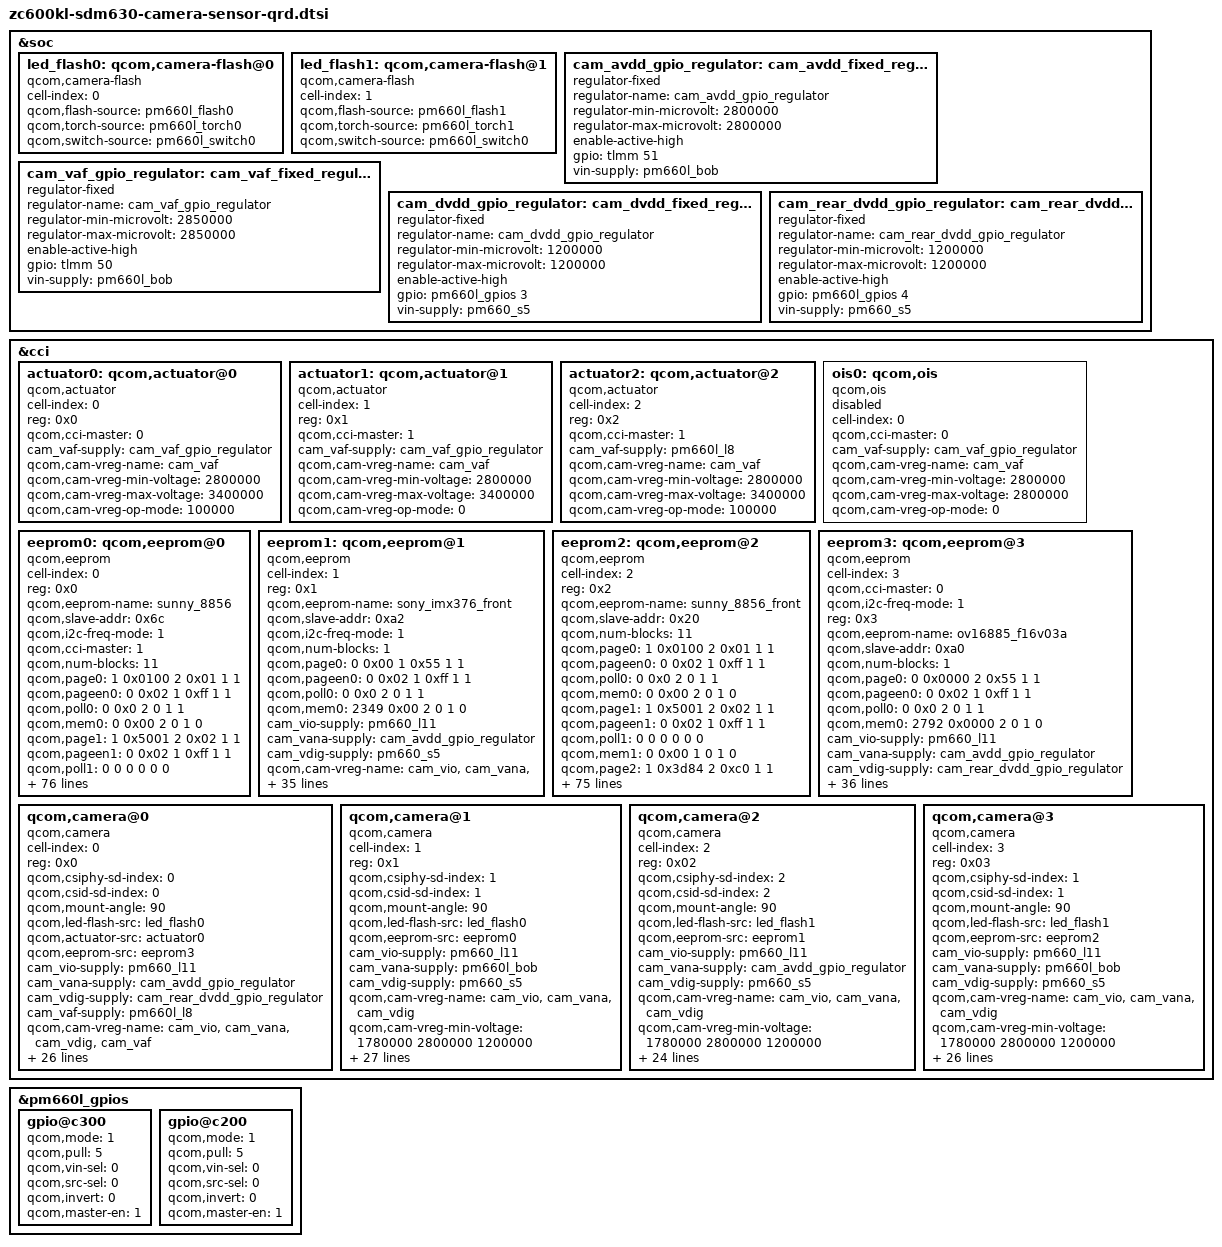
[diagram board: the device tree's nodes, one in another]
/*
 * Copyright (c) 2017, The Linux Foundation. All rights reserved.
 *
 * This program is free software; you can redistribute it and/or modify
 * it under the terms of the GNU General Public License version 2 and
 * only version 2 as published by the Free Software Foundation.
 *
 * This program is distributed in the hope that it will be useful,
 * but WITHOUT ANY WARRANTY; without even the implied warranty of
 * MERCHANTABILITY or FITNESS FOR A PARTICULAR PURPOSE.  See the
 * GNU General Public License for more details.
 */

&soc {
	led_flash0: qcom,camera-flash@0 {
		cell-index = <0>;
		compatible = "qcom,camera-flash";
		qcom,flash-source = <&pm660l_flash0>;
		qcom,torch-source = <&pm660l_torch0>;
		qcom,switch-source = <&pm660l_switch0>;
		status = "ok";
	};

	led_flash1: qcom,camera-flash@1 {
		cell-index = <1>;
		compatible = "qcom,camera-flash";
		qcom,flash-source = <&pm660l_flash1>;
		qcom,torch-source = <&pm660l_torch1>;
		qcom,switch-source = <&pm660l_switch0>;
		status = "ok";
	};
	cam_avdd_gpio_regulator: cam_avdd_fixed_regulator {
		compatible = "regulator-fixed";
		regulator-name = "cam_avdd_gpio_regulator";
		regulator-min-microvolt = <2800000>;
		regulator-max-microvolt = <2800000>;
		enable-active-high;
		gpio = <&tlmm 51 0>;
		vin-supply = <&pm660l_bob>;
	};

	cam_vaf_gpio_regulator: cam_vaf_fixed_regulator {
		compatible = "regulator-fixed";
		regulator-name = "cam_vaf_gpio_regulator";
		regulator-min-microvolt = <2850000>;
		regulator-max-microvolt = <2850000>;
		enable-active-high;
		gpio = <&tlmm 50 0>;
		vin-supply = <&pm660l_bob>;
	};
	cam_dvdd_gpio_regulator: cam_dvdd_fixed_regulator {
		compatible = "regulator-fixed";
		regulator-name = "cam_dvdd_gpio_regulator";
		regulator-min-microvolt = <1200000>;
		regulator-max-microvolt = <1200000>;
		enable-active-high;
		gpio = <&pm660l_gpios 3 0>;
		vin-supply = <&pm660_s5>;
	};
	cam_rear_dvdd_gpio_regulator: cam_rear_dvdd_fixed_regulator {
		compatible = "regulator-fixed";
		regulator-name = "cam_rear_dvdd_gpio_regulator";
		regulator-min-microvolt = <1200000>;
		regulator-max-microvolt = <1200000>;
		enable-active-high;
		gpio = <&pm660l_gpios 4 0>;
		vin-supply = <&pm660_s5>;
	};
};

&cci {
	actuator0: qcom,actuator@0 {
		cell-index = <0>;
		reg = <0x0>;
		compatible = "qcom,actuator";
		qcom,cci-master = <0>;
		cam_vaf-supply = <&cam_vaf_gpio_regulator>;
		qcom,cam-vreg-name = "cam_vaf";
		qcom,cam-vreg-min-voltage = <2800000>;
		qcom,cam-vreg-max-voltage = <3400000>;
		qcom,cam-vreg-op-mode = <100000>;
	};

	actuator1: qcom,actuator@1 {
		cell-index = <1>;
		reg = <0x1>;
		compatible = "qcom,actuator";
		qcom,cci-master = <1>;
		cam_vaf-supply = <&cam_vaf_gpio_regulator>;
		qcom,cam-vreg-name = "cam_vaf";
		qcom,cam-vreg-min-voltage = <2800000>;
		qcom,cam-vreg-max-voltage = <3400000>;
		qcom,cam-vreg-op-mode = <0>;
	};

	actuator2: qcom,actuator@2 {
		cell-index = <2>;
		reg = <0x2>;
		compatible = "qcom,actuator";
		qcom,cci-master = <1>;
		cam_vaf-supply = <&pm660l_l8>;
		qcom,cam-vreg-name = "cam_vaf";
		qcom,cam-vreg-min-voltage = <2800000>;
		qcom,cam-vreg-max-voltage = <3400000>;
		qcom,cam-vreg-op-mode = <100000>;
	};
	ois0: qcom,ois {
		cell-index = <0>;
		compatible = "qcom,ois";
		qcom,cci-master = <0>;
		cam_vaf-supply = <&cam_vaf_gpio_regulator>;
		qcom,cam-vreg-name = "cam_vaf";
		qcom,cam-vreg-min-voltage = <2800000>;
		qcom,cam-vreg-max-voltage = <2800000>;
		qcom,cam-vreg-op-mode = <0>;
		status = "disabled";
	};

	eeprom0: qcom,eeprom@0 {
		cell-index = <0>;
		reg = <0x0>;
		compatible = "qcom,eeprom";
		
        //add by allenyao
		qcom,eeprom-name = "sunny_8856";
		qcom,slave-addr = <0x6c>;
		qcom,i2c-freq-mode=<1>;
		qcom,cci-master = <1>;
		qcom,num-blocks = <11>;
		
		qcom,page0 = <1 0x0100 2 0x01 1 1>;
		qcom,pageen0 = <0 0x02 1 0xff 1 1>;
		qcom,poll0 = <0 0x0 2 0 1 1>;
		qcom,mem0 = <0 0x00 2 0 1 0>;

		qcom,page1 = <1 0x5001 2 0x02 1 1>;
		qcom,pageen1 = <0 0x02 1 0xff 1 1>;
		qcom,poll1 = <0 0 0 0 0 0>;
		qcom,mem1 = <0 0x00 1 0 1 0>;
		
		qcom,page2 = <1 0x3d84 2 0xc0 1 1>;
		qcom,pageen2 = <0 0x02 1 0xff 1 1>;
		qcom,poll2 = <0 0 0 0 0 0>;
		qcom,mem2 = <0 0x00 1 0 1 0>;

		qcom,page3 = <1 0x3d88 2 0x70 1 1>;//start high add
		qcom,pageen3 = <0 0x02 1 0xff 1 1>;
		qcom,poll3 = <0 0 0 0 0 0>;
		qcom,mem3 = <0 0x00 1 0 1 0>;
		
		qcom,page4 = <1 0x3d89 2 0x10 1 1>;//start low add
		qcom,pageen4 = <0 0x02 1 0xff 1 1>;
		qcom,poll4 = <0 0 0 0 0 0>;
		qcom,mem4 = <0 0x00 1 0 1 0>;
		
		qcom,page5 = <1 0x3d8a 2 0x72 1 1>;//end high add
		qcom,pageen5 = <0 0x02 1 0xff 1 1>;
		qcom,poll5 = <0 0 0 0 0 0>;
		qcom,mem5 = <0 0x00 1 0 1 0>;

		qcom,page6 = <1 0x3d8b 2 0x03 1 1>;//end low add
		qcom,pageen6 = <0 0x02 1 0xff 1 1>;
		qcom,poll6 = <0 0 0 0 0 0>;
		qcom,mem6 = <0 0x00 1 0 1 0>;

		qcom,page7 = <1 0x3d81 2 0x01 1 10>;//load otp data into buffer
		qcom,pageen7 = <0 0x02 1 0xff 1 1>;
		qcom,poll7 = <0 0 0 0 0 0>;
		qcom,mem7 = <0 0x7203 2 0 1 0>;

		qcom,page8 = <0 0x00 1 0x11 1 1>;
		qcom,pageen8 = <0 0x02 1 0xff 1 1>;
		qcom,poll8 = <0 0 0 0 0 0>;
		qcom,mem8 = <500 0x7010 2 0 1 0>; //read data
		
		qcom,page9 = <0 0x00 1 0x11 1 1>;
		qcom,pageen9 = <0 0x02 1 0xff 1 1>;
		qcom,poll9 = <0 0 0 0 0 0>;
		qcom,mem9 = <0 0x00 1 0 1 0>;
		qcom,clear9 = <500 0x7010 2 0 1 0>; //clear buff

		qcom,page10 = <1 0x5001 2 0x0a 1 1>;
		qcom,pageen10 = <0 0x02 1 0xff 1 1>;
		qcom,poll10 = <0 0 0 0 0 0>;
		qcom,mem10 = <0 0x7203 2 0 1 0>;
		//end 

		cam_vio-supply = <&pm660_l11>;
		cam_vana-supply = <&pm660l_bob>;
		cam_vdig-supply = <&pm660_s5>;
		qcom,cam-vreg-name = "cam_vio", "cam_vana", "cam_vdig";
		qcom,cam-vreg-min-voltage = <1780000 2800000 1200000>;
		qcom,cam-vreg-max-voltage = <1950000 2800000 1200000>;
		qcom,cam-vreg-op-mode = <105000 80000 100000>;
		qcom,gpio-no-mux = <0>;
		pinctrl-names = "cam_default", "cam_suspend";
		pinctrl-0 = <&cam_sensor_mclk2_active
				 &cam_sensor_rear2_active>;
		pinctrl-1 = <&cam_sensor_mclk2_suspend
				 &cam_sensor_rear2_suspend>;
		gpios = <&tlmm 34 0>,
			<&tlmm 64 0>,
		    <&tlmm 40 0>,
		    <&pm660l_gpios 4 0>,
		    <&tlmm 51 0>;
		qcom,gpio-reset = <1>;
		qcom,gpio-standby = <2>;
		qcom,gpio-vdig = <3>;
		qcom,gpio-vana = <4>;
		qcom,gpio-req-tbl-num = <0 1 2 3 4>;
		qcom,gpio-req-tbl-flags = <1 0 0 0 0>;
		qcom,gpio-req-tbl-label = "CAMIF_MCLK2",
					  "CAM_RESET",
					  "CAM_STANDBY",
					  "CAM_VDIG",
					  "CAM_VANA";
		qcom,sensor-position = <0>;
		qcom,sensor-mode = <0>;

		qcom,cam-power-seq-type = "sensor_gpio",
			"sensor_gpio", "sensor_vreg",
			"sensor_vreg", "sensor_clk",
			"sensor_gpio";
		qcom,cam-power-seq-val = "sensor_gpio_reset",
			"sensor_gpio_vana", "cam_vdig",
			"cam_vio",
			"sensor_cam_mclk",
			"sensor_gpio_reset";
		qcom,cam-power-seq-cfg-val = <0  1 1 1 24000000 1>;
		qcom,cam-power-seq-delay = <10 10 10 10 10 5>;

		status = "ok";

		clocks = <&clock_mmss MCLK2_CLK_SRC>,
			<&clock_mmss MMSS_CAMSS_MCLK2_CLK>;
		clock-names = "cam_src_clk", "cam_clk";
		qcom,clock-rates = <24000000 0>;
	};

	eeprom1: qcom,eeprom@1 {
		cell-index = <1>;
		reg = <0x1>;
		compatible = "qcom,eeprom";

		qcom,eeprom-name = "sony_imx376_front";
		qcom,slave-addr = <0xa2>;
		qcom,i2c-freq-mode=<1>;
		qcom,num-blocks = <1>;	
		qcom,page0 = <0 0x00 1 0x55 1 1>;
		qcom,pageen0 = <0 0x02 1 0xff 1 1>;
		qcom,poll0 = <0 0x0 2 0 1 1>;
		qcom,mem0 = <2349 0x00 2 0 1 0>;
		
		cam_vio-supply = <&pm660_l11>;
		cam_vana-supply = <&cam_avdd_gpio_regulator>;
		cam_vdig-supply = <&pm660_s5>;
		qcom,cam-vreg-name = "cam_vio", "cam_vana", "cam_vdig";
		qcom,cam-vreg-min-voltage = <1780000 2800000 1200000>;
		qcom,cam-vreg-max-voltage = <1950000 2800000 1200000>;
		qcom,cam-vreg-op-mode = <105000 80000 100000>;
		qcom,gpio-no-mux = <0>;
		pinctrl-names = "cam_default", "cam_suspend";
		pinctrl-0 = <&cam_sensor_mclk0_active
				 &cam_sensor_front_active>;
		pinctrl-1 = <&cam_sensor_mclk0_suspend
				 &cam_sensor_front_suspend>;
		gpios = <&tlmm 32 0>,
			    <&tlmm 48 0>,
			    <&tlmm 52 0>,
			    <&pm660l_gpios 3 0>,
			    <&tlmm 51 0>;
		qcom,gpio-reset = <1>;
		qcom,gpio-standby = <2>;
		qcom,gpio-vdig = <3>;
		qcom,gpio-vana = <4>;
		qcom,gpio-req-tbl-num = <0 1 2 3 4>;
		qcom,gpio-req-tbl-flags = <1 0 0 0 0>;
		qcom,gpio-req-tbl-label = "CAMIF_MCLK0",
					"CAM_RESET2",
					"CAM_STANDBY2",
					"CAM_VDIG",
					"CAM_VANA";
		qcom,sensor-position = <1>;
		qcom,sensor-mode = <0>;
		qcom,cci-master = <0>;
		status = "ok";
		qcom,cam-power-seq-type = "sensor_gpio",
			"sensor_gpio", "sensor_gpio",
			"sensor_vreg", "sensor_clk",
			"sensor_gpio";
		qcom,cam-power-seq-val = "sensor_gpio_reset",
			"sensor_gpio_vana", "sensor_gpio_vdig",
			"cam_vio",
			"sensor_cam_mclk",
			"sensor_gpio_reset";
		qcom,cam-power-seq-cfg-val = <0  1 1 1 24000000 1>;
		qcom,cam-power-seq-delay = <10 10 10 10 10 5>;

		clocks = <&clock_mmss MCLK0_CLK_SRC>,
			<&clock_mmss MMSS_CAMSS_MCLK0_CLK>;
		clock-names = "cam_src_clk", "cam_clk";
		qcom,clock-rates = <24000000 0>;
	};

	eeprom2: qcom,eeprom@2 {
		cell-index = <2>;
		reg = <0x2>;
		compatible = "qcom,eeprom";
        //add by allenyao
		qcom,eeprom-name = "sunny_8856_front"; //Bug316366, sunhushan.wt, MODIFY, 2017.11.03, modify for 8856's OTP
		//compatible = "qcom,eeprom";
		qcom,slave-addr = <0x20>;
		qcom,num-blocks = <11>;
		
		qcom,page0 = <1 0x0100 2 0x01 1 1>;
		qcom,pageen0 = <0 0x02 1 0xff 1 1>;
		qcom,poll0 = <0 0x0 2 0 1 1>;
		qcom,mem0 = <0 0x00 2 0 1 0>;

		qcom,page1 = <1 0x5001 2 0x02 1 1>;
		qcom,pageen1 = <0 0x02 1 0xff 1 1>;
		qcom,poll1 = <0 0 0 0 0 0>;
		qcom,mem1 = <0 0x00 1 0 1 0>;
		
		qcom,page2 = <1 0x3d84 2 0xc0 1 1>;
		qcom,pageen2 = <0 0x02 1 0xff 1 1>;
		qcom,poll2 = <0 0 0 0 0 0>;
		qcom,mem2 = <0 0x00 1 0 1 0>;

		qcom,page3 = <1 0x3d88 2 0x70 1 1>;//start high add
		qcom,pageen3 = <0 0x02 1 0xff 1 1>;
		qcom,poll3 = <0 0 0 0 0 0>;
		qcom,mem3 = <0 0x00 1 0 1 0>;
		
		qcom,page4 = <1 0x3d89 2 0x10 1 1>;//start low add
		qcom,pageen4 = <0 0x02 1 0xff 1 1>;
		qcom,poll4 = <0 0 0 0 0 0>;
		qcom,mem4 = <0 0x00 1 0 1 0>;
		
		qcom,page5 = <1 0x3d8a 2 0x72 1 1>;//end high add
		qcom,pageen5 = <0 0x02 1 0xff 1 1>;
		qcom,poll5 = <0 0 0 0 0 0>;
		qcom,mem5 = <0 0x00 1 0 1 0>;

		qcom,page6 = <1 0x3d8b 2 0x03 1 1>;//end low add
		qcom,pageen6 = <0 0x02 1 0xff 1 1>;
		qcom,poll6 = <0 0 0 0 0 0>;
		qcom,mem6 = <0 0x00 1 0 1 0>;

		qcom,page7 = <1 0x3d81 2 0x01 1 10>;//load otp data into buffer
		qcom,pageen7 = <0 0x02 1 0xff 1 1>;
		qcom,poll7 = <0 0 0 0 0 0>;
		qcom,mem7 = <0 0x7203 2 0 1 0>;

		qcom,page8 = <0 0x00 1 0x11 1 1>;
		qcom,pageen8 = <0 0x02 1 0xff 1 1>;
		qcom,poll8 = <0 0 0 0 0 0>;
		qcom,mem8 = <500 0x7010 2 0 1 0>; //read data
		
		qcom,page9 = <0 0x00 1 0x11 1 1>;
		qcom,pageen9 = <0 0x02 1 0xff 1 1>;
		qcom,poll9 = <0 0 0 0 0 0>;
		qcom,mem9 = <0 0x00 1 0 1 0>;
		qcom,clear9 = <500 0x7010 2 0 1 0>; //clear buff

		qcom,page10 = <1 0x5001 2 0x0a 1 1>;
		qcom,pageen10 = <0 0x02 1 0xff 1 1>;
		qcom,poll10 = <0 0 0 0 0 0>;
		qcom,mem10 = <0 0x7203 2 0 1 0>;
		//end 
		cam_vio-supply = <&pm660_l11>;
		cam_vana-supply = <&pm660l_bob>;
		cam_vdig-supply = <&pm660_s5>;
		qcom,cam-vreg-name = "cam_vio", "cam_vana", "cam_vdig";
		qcom,cam-vreg-min-voltage = <1780000 2800000 1200000>;
		qcom,cam-vreg-max-voltage = <1950000 2800000 1200000>;
		qcom,cam-vreg-op-mode = <105000 80000 100000>;
		qcom,gpio-no-mux = <0>;
		pinctrl-names = "cam_default", "cam_suspend";
		pinctrl-0 = <&cam_sensor_mclk1_active
				 &cam_sensor_front_iris_active>;
		pinctrl-1 = <&cam_sensor_mclk1_suspend
				 &cam_sensor_front_iris_suspend>;
		gpios = <&tlmm 33 0>,
			<&tlmm 47 0>,
            <&tlmm 49 0>,
            <&pm660l_gpios 4 0>;
		qcom,gpio-reset = <1>;
		qcom,gpio-standby = <2>;
		qcom,gpio-vdig = <3>;
		qcom,gpio-req-tbl-num = <0 1 2 3>;
		qcom,gpio-req-tbl-flags = <1 0 0 0>;
		qcom,gpio-req-tbl-label = "CAMIF_MCLK",
					"CAM_RESET3",
		            "CAM_STANDBY3",
				    "CAM_VDIG";

		qcom,sensor-position = <1>;
		qcom,sensor-mode = <0>;
		qcom,cci-master = <1>;
		qcom,i2c-freq-mode=<1>;

		qcom,cam-power-seq-type = "sensor_gpio",
			"sensor_gpio", "sensor_vreg",
			"sensor_vreg", "sensor_clk",
			"sensor_gpio";
		qcom,cam-power-seq-val = "sensor_gpio_reset",
			"sensor_gpio_vana", "cam_vdig",
			"cam_vio",
			"sensor_cam_mclk",
			"sensor_gpio_reset";
		qcom,cam-power-seq-cfg-val = <0  1 1 1 24000000 1>;
		qcom,cam-power-seq-delay = <10 10 10 10 10 5>;	

		status = "ok";
		clocks = <&clock_mmss MCLK1_CLK_SRC>,
			<&clock_mmss MMSS_CAMSS_MCLK1_CLK>;
		clock-names = "cam_src_clk", "cam_clk";
		qcom,clock-rates = <24000000 0>;
 	};

    eeprom3: qcom,eeprom@3{
		cell-index = <3>;
		compatible = "qcom,eeprom";
		qcom,cci-master = <0>;
		qcom,i2c-freq-mode=<1>;
		reg = <0x3>;
		qcom,eeprom-name = "ov16885_f16v03a";
		qcom,slave-addr = <0xa0>;
		qcom,num-blocks = <1>;

        qcom,page0 = <0 0x0000 2 0x55 1 1>;
		qcom,pageen0 = <0 0x02 1 0xff 1 1>;
		qcom,poll0 = <0 0x0 2 0 1 1>;
		qcom,mem0 = <2792 0x0000 2 0 1 0>;

		cam_vio-supply = <&pm660_l11>;
		cam_vana-supply = <&cam_avdd_gpio_regulator>;
		cam_vdig-supply = <&cam_rear_dvdd_gpio_regulator>;
		cam_vaf-supply = <&pm660l_l8>;
		qcom,cam-vreg-name = "cam_vio", "cam_vana", "cam_vdig", "cam_vaf";
		qcom,cam-vreg-min-voltage = <1780000 2800000 1200000 2850000>;
		qcom,cam-vreg-max-voltage = <1950000 2800000 1200000 2850000>;
		qcom,cam-vreg-op-mode = <105000 80000 100000 100000>;
		qcom,gpio-no-mux = <0>;
		pinctrl-names = "cam_default", "cam_suspend";
		pinctrl-0 = <&cam_sensor_mclk3_active
				 &cam_sensor_rear_active>;
		pinctrl-1 = <&cam_sensor_mclk3_suspend
				 &cam_sensor_rear_suspend>;
		gpios = <&tlmm 35 0>,
			    <&tlmm 46 0>,
			    <&tlmm 44 0>,
			    <&pm660l_gpios 4 0>;
		qcom,gpio-reset = <1>;
		qcom,gpio-standby = <2>;
		qcom,gpio-vdig = <3>;
		qcom,gpio-req-tbl-num = <0 1 2 3>;
		qcom,gpio-req-tbl-flags = <1 0 0 0>;
		qcom,gpio-req-tbl-label = "CAMIF_MCLK3",
					              "CAM_RESET0",
								  "CAM_STANDBY0",
								  "CAM_VDIG";
		qcom,sensor-position = <0>;
		qcom,sensor-mode = <0>;
		qcom,cam-power-seq-type = "sensor_gpio",
			"sensor_gpio", "sensor_gpio",
			"sensor_vreg", "sensor_clk",
			"sensor_gpio";
		qcom,cam-power-seq-val = "sensor_gpio_reset",
			"sensor_gpio_vana", "sensor_gpio_vdig",
			"cam_vio",
			"sensor_cam_mclk",
			"sensor_gpio_reset";
		qcom,cam-power-seq-cfg-val = <0  1 1 1 24000000 1>;
		qcom,cam-power-seq-delay = <10 10 10 10 10 5>;
		status = "ok";
		clocks = <&clock_mmss MCLK3_CLK_SRC>,
				<&clock_mmss MMSS_CAMSS_MCLK3_CLK>;
		clock-names = "cam_src_clk", "cam_clk";
		qcom,clock-rates = <24000000 0>;
	};


	qcom,camera@0 {
		cell-index = <0>;
		compatible = "qcom,camera";
		reg = <0x0>;
		qcom,csiphy-sd-index = <0>;
		qcom,csid-sd-index = <0>;
		qcom,mount-angle = <90>;
		qcom,led-flash-src = <&led_flash0>;
		qcom,actuator-src = <&actuator0>;
		//qcom,ois-src = <&ois0>;
		qcom,eeprom-src = <&eeprom3>;
		cam_vio-supply = <&pm660_l11>;
		cam_vana-supply = <&cam_avdd_gpio_regulator>;
		cam_vdig-supply = <&cam_rear_dvdd_gpio_regulator>;
		cam_vaf-supply = <&pm660l_l8>;
		qcom,cam-vreg-name = "cam_vio", "cam_vana", "cam_vdig", "cam_vaf";
		qcom,cam-vreg-min-voltage = <1780000 2800000 1200000 2850000>;
		qcom,cam-vreg-max-voltage = <1950000 2800000 1200000 2850000>;
		qcom,cam-vreg-op-mode = <105000 80000 100000 100000>;
		qcom,gpio-no-mux = <0>;
		pinctrl-names = "cam_default", "cam_suspend";
		pinctrl-0 = <&cam_sensor_mclk3_active
				 &cam_sensor_rear_active>;
		pinctrl-1 = <&cam_sensor_mclk3_suspend
				 &cam_sensor_rear_suspend>;
		gpios = <&tlmm 35 0>,
			    <&tlmm 46 0>,
			    <&tlmm 44 0>,
			<&pm660l_gpios 4 0>;
		qcom,gpio-reset = <1>;
		qcom,gpio-standby = <2>;
		qcom,gpio-vdig = <3>;
		qcom,gpio-req-tbl-num = <0 1 2 3>;
		qcom,gpio-req-tbl-flags = <1 0 0 0>;
		qcom,gpio-req-tbl-label = "CAMIF_MCLK3",
					"CAM_RESET0",
					"CAM_STANDBY0",
					"CAM_VDIG";
		qcom,sensor-position = <0>;
		qcom,sensor-mode = <0>;
		qcom,cci-master = <0>;
		status = "ok";
		clocks = <&clock_mmss MCLK3_CLK_SRC>,
				<&clock_mmss MMSS_CAMSS_MCLK3_CLK>;
		clock-names = "cam_src_clk", "cam_clk";
		qcom,clock-rates = <24000000 0>;
	};

	qcom,camera@1 {
		cell-index = <1>;
		compatible = "qcom,camera";
		reg = <0x1>;
		qcom,csiphy-sd-index = <1>;
		qcom,csid-sd-index = <1>;
		qcom,mount-angle = <90>;
		qcom,led-flash-src = <&led_flash0>;
		//qcom,actuator-src = <&actuator1>;
		qcom,eeprom-src = <&eeprom0>;
		cam_vio-supply = <&pm660_l11>;
		cam_vana-supply = <&pm660l_bob>;
		cam_vdig-supply = <&pm660_s5>;
		qcom,cam-vreg-name = "cam_vio", "cam_vana", "cam_vdig";
		qcom,cam-vreg-min-voltage = <1780000 2800000 1200000>;
		qcom,cam-vreg-max-voltage = <1950000 2800000 1200000>;
		qcom,cam-vreg-op-mode = <105000 80000 100000>;
		qcom,gpio-no-mux = <0>;
		pinctrl-names = "cam_default", "cam_suspend";
		pinctrl-0 = <&cam_sensor_mclk2_active
				 &cam_sensor_rear2_active>;
		pinctrl-1 = <&cam_sensor_mclk2_suspend
				 &cam_sensor_rear2_suspend>;
		gpios = <&tlmm 34 0>,
			<&tlmm 64 0>,
		    <&tlmm 40 0>,
            <&pm660l_gpios 4 0>,
            <&tlmm 51 0>,
 			<&tlmm 25 0>,//cam witch diable
 			<&tlmm 24 0>;//FCAM_SEL
		qcom,gpio-reset = <1>;
		qcom,gpio-standby = <2>;
		qcom,gpio-vdig = <3>;
		qcom,gpio-vana = <4>;
		qcom,gpio-custom1 = <5>;
		qcom,gpio-custom2 = <6>;
		qcom,gpio-req-tbl-num = <0 1 2 3 4 5 6>;
		qcom,gpio-req-tbl-flags = <1 0 0 0 0 0 0>;
		qcom,gpio-req-tbl-label = "CAMIF_MCLK2",
					"CAM_RESET",
					"CAM_STANDBY",
					"CAM_VDIG",
					"CAM_VANA",
					"CAM_CUSTOM1",
					"CAM_CUSTOM2"; 
		qcom,sensor-position = <0>;
		qcom,sensor-mode = <0>;
		qcom,cci-master = <1>;
		status = "ok";
		clocks = <&clock_mmss MCLK2_CLK_SRC>,
			<&clock_mmss MMSS_CAMSS_MCLK2_CLK>;
		clock-names = "cam_src_clk", "cam_clk";
		qcom,clock-rates = <24000000 0>;
	};

	qcom,camera@2 {
		cell-index = <2>;
		compatible = "qcom,camera";
		reg = <0x02>;
		qcom,csiphy-sd-index = <2>;
		qcom,csid-sd-index = <2>;
		qcom,mount-angle = <90>;
		qcom,led-flash-src = <&led_flash1>;
		qcom,eeprom-src = <&eeprom1>;
		cam_vio-supply = <&pm660_l11>;
		cam_vana-supply = <&cam_avdd_gpio_regulator>;
		cam_vdig-supply = <&pm660_s5>;
		qcom,cam-vreg-name = "cam_vio", "cam_vana", "cam_vdig";
		qcom,cam-vreg-min-voltage = <1780000 2800000 1200000>;
		qcom,cam-vreg-max-voltage = <1950000 2800000 1200000>;
		qcom,cam-vreg-op-mode = <105000 80000 100000>;
		qcom,gpio-no-mux = <0>;
		pinctrl-names = "cam_default", "cam_suspend";
		pinctrl-0 = <&cam_sensor_mclk0_active
				 &cam_sensor_front_active>;
		pinctrl-1 = <&cam_sensor_mclk0_suspend
				 &cam_sensor_front_suspend>;
		gpios = <&tlmm 32 0>,
			    <&tlmm 48 0>,
			    <&tlmm 52 0>,
			    <&pm660l_gpios 3 0>,
			    <&tlmm 51 0>;
		qcom,gpio-reset = <1>;
		qcom,gpio-standby = <2>;
		qcom,gpio-vdig = <3>;
		qcom,gpio-vana = <4>;
		qcom,gpio-req-tbl-num = <0 1 2 3 4>;
		qcom,gpio-req-tbl-flags = <1 0 0 0 0>;
		qcom,gpio-req-tbl-label = "CAMIF_MCLK0",
					"CAM_RESET2",
					"CAM_STANDBY2",
					"CAM_VDIG",
					"CAM_VANA";
		qcom,sensor-position = <1>;
		qcom,sensor-mode = <0>;
		qcom,cci-master = <0>;
		status = "ok";
		clocks = <&clock_mmss MCLK0_CLK_SRC>,
			<&clock_mmss MMSS_CAMSS_MCLK0_CLK>;
		clock-names = "cam_src_clk", "cam_clk";
		qcom,clock-rates = <24000000 0>;
	};

	qcom,camera@3 {
		cell-index = <3>;
		compatible = "qcom,camera";
		reg = <0x03>;
		qcom,csiphy-sd-index = <1>;
		qcom,csid-sd-index = <1>;
		qcom,mount-angle = <90>;
		//qcom,actuator-src = <&actuator2>;
		qcom,led-flash-src = <&led_flash1>;
		qcom,eeprom-src = <&eeprom2>;
		cam_vio-supply = <&pm660_l11>;
		cam_vana-supply = <&pm660l_bob>;
		cam_vdig-supply = <&pm660_s5>;
		qcom,cam-vreg-name = "cam_vio", "cam_vana", "cam_vdig";
		qcom,cam-vreg-min-voltage = <1780000 2800000 1200000>;
		qcom,cam-vreg-max-voltage = <1950000 2800000 1200000>;
		qcom,cam-vreg-op-mode = <105000 80000 100000>;
		qcom,gpio-no-mux = <0>;
		pinctrl-names = "cam_default", "cam_suspend";
		pinctrl-0 = <&cam_sensor_mclk1_active
				 &cam_sensor_front_iris_active>;
		pinctrl-1 = <&cam_sensor_mclk1_suspend
				 &cam_sensor_front_iris_suspend>;
		gpios = <&tlmm 33 0>,
			<&tlmm 47 0>,
            <&tlmm 49 0>,
            <&pm660l_gpios 4 0>,
 			<&tlmm 25 0>,//cam witch diable
 			<&tlmm 24 0>;//FCAM_SEL
		qcom,gpio-reset = <1>;
		qcom,gpio-standby = <2>;
		qcom,gpio-vdig = <3>;
 		qcom,gpio-custom1 = <4>;
 		qcom,gpio-custom2 = <5>;
		qcom,gpio-req-tbl-num = <0 1 2 3 4 5>;
		qcom,gpio-req-tbl-flags = <1 0 0 0 0 0>;
		qcom,gpio-req-tbl-label = "CAMIF_MCLK",
					"CAM_RESET3",
		            "CAM_STANDBY3",
				    "CAM_VDIG",
			        "CAM_CUSTOM1",
			     	"CAM_CUSTOM2";
		qcom,sensor-position = <1>;
		qcom,sensor-mode = <0>;
		qcom,cci-master = <1>;
		status = "ok";
		clocks = <&clock_mmss MCLK1_CLK_SRC>,
			<&clock_mmss MMSS_CAMSS_MCLK1_CLK>;
		clock-names = "cam_src_clk", "cam_clk";
		qcom,clock-rates = <24000000 0>;
	};
};

&pm660l_gpios {
	gpio@c300 { /* GPIO4 -CAMERA SENSOR 0 VDIG*/
		qcom,mode = <1>;                /* Output */
		qcom,pull = <5>;                /* No Pull */
		qcom,vin-sel = <0>;             /* VIN1 GPIO_LV */
		qcom,src-sel = <0>;             /* GPIO */
		qcom,invert = <0>;              /* Invert */
		qcom,master-en = <1>;           /* Enable GPIO */
		status = "ok";
	};

	gpio@c200 { /* GPIO3 -CAMERA SENSOR 2 VDIG*/
		qcom,mode = <1>;                /* Output */
		qcom,pull = <5>;                /* No Pull */
		qcom,vin-sel = <0>;             /* VIN1 GPIO_LV */
		qcom,src-sel = <0>;             /* GPIO */
		qcom,invert = <0>;              /* Invert */
		qcom,master-en = <1>;           /* Enable GPIO */
		status = "ok";
	};
};
